# psoc4hvpaspm10 register map
Vendor: Infineon Technologies; Series: PSOC4HVPASPM10; File version: 1.0
CPU: CM0PLUS r0p1, little endian, MPU, no FPU, VTOR, 2 interrupt priority bits, 32 interrupts
Registers are 32-bit, read-write, reset 0x0 unless marked. A register's access mark holds for its fields unless they carry their own. Offsets are from the block's base; [hi:lo] are bit positions; lines under a group give offsets from that group.

## CANFD0 (part 2 of 3) — CAN Controller
Base 0x40220000
0x00 CH group — FIFO wrapper around M_TTCAN 3PIP, to enable DMA
  0x00 M_TTCAN group — TTCAN 3PIP, includes FD
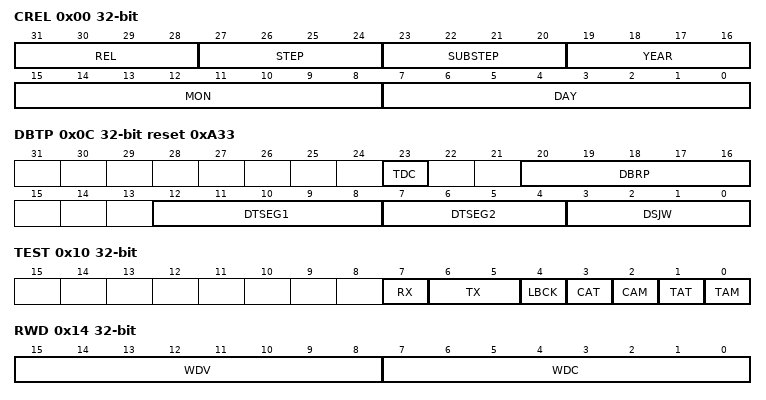
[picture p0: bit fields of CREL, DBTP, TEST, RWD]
    0x00 CREL ro — Core Release Register
      [31:28] REL — Core Release One digit, BCD-coded.
      [27:24] STEP — Step of Core Release One digit, BCD-coded.
      [23:20] SUBSTEP — Sub-step of Core Release One digit, BCD-coded.
      [19:16] YEAR — Time Stamp Year One digit, BCD-coded. This field is set by generic parameter on M_TTCAN synthesis.
      [15:8] MON — Time Stamp Month Two digits, BCD-coded. This field is set by generic parameter on M_TTCAN synthesis.
      [7:0] DAY — Time Stamp Day Two digits, BCD-coded. This field is set by generic parameter on M_TTCAN synthesis.
    0x04 ENDN ro reset 0x87654321 — Endian Register
      [31:0] ETV — Endianness Test Value The endianness test value is 0x87654321.
    0x0C DBTP reset 0xA33 — Data Bit Timing & Prescaler Register
      [23] TDC — Transmitter Delay Compensation 0= Transmitter Delay Compensation disabled 1= Transmitter Delay Compensation enabled
      [20:16] DBRP — Data Bit Rate Prescaler 0x00-0x1F The value by which the oscillator frequency is divided for generating the bit time quanta. The bit time is built up from a multiple of this quanta. Valid values for the Bit Rate Prescaler are 0 to 31. The actual interpretation by the hardware of this value is such that one more than the value programmed here is used.
      [12:8] DTSEG1 — Data time segment before sample point 0x00-0x1F Valid values are 0 to 31. The actual interpretation by the hardware of this value is such that one more than the programmed value is used.
      [7:4] DTSEG2 — Data time segment after sample point 0x0-0xF Valid values are 0 to 15. The actual interpretation by the hardware of this value is such that one more than the programmed value is used.
      [3:0] DSJW — Data (Re)Synchronization Jump Width 0x0-0xF Valid values are 0 to 15. The actual interpretation by the hardware of this value is such that one more than the value programmed here is used.
    0x10 TEST (reset mask 0x7F)
      [7] RX ro — Receive Pin Monitors the actual value of pin m_ttcan_rx 0= The CAN bus is dominant (m_ttcan_rx = '0') 1= The CAN bus is recessive (m_ttcan_rx = '1')
      [6:5] TX — Control of Transmit Pin 00 Reset value, m_ttcan_tx controlled by the CAN Core, updated at the end of the CAN bit time 01 Sample Point can be monitored at pin m_ttcan_tx 10 Dominant ('0') level at pin m_ttcan_tx 11 Recessive ('1') at pin m_ttcan_tx
      [4] LBCK — Loop Back Mode 0= Reset value, Loop Back Mode is disabled 1= Loop Back Mode is enabled (see Section 3.1.9, Test Modes)
      [3] CAT — ASC is not supported by M_TTCAN Check ASC Transmit Control Monitors level at output pin m_ttcan_asct. 0= Output pin m_ttcan_asct = '0'
      [2] CAM — ASC is not supported by M_TTCAN Check ASC Multiplexer Control Monitors level at output pin m_ttcan_ascm. 0= Output pin m_ttcan_ascm = '0' 1= Output pin m_ttcan_ascm = '1'
      [1] TAT — ASC is not supported by M_TTCAN Test ASC Transmit Control Controls output pin m_ttcan_asct in test mode, ORed with the signal from the FSE 0= Level at pin m_ttcan_asct controlled by FSE 1= Level at pin m_ttcan_asct = '1'
      [0] TAM — ASC is not supported by M_TTCAN Test ASC Multiplexer Control Controls output pin m_ttcan_ascm in test mode, ORed with the signal from the FSE 0= Level at pin m_ttcan_ascm controlled by FSE 1= Level at pin m_ttcan_ascm = '1'
    0x14 RWD — RAM Watchdog
      [15:8] WDV ro — Watchdog Value Actual Message RAM Watchdog Counter Value.
      [7:0] WDC — Watchdog Configuration Start value of the Message RAM Watchdog Counter. With the reset value of '00' the counter is disabled.
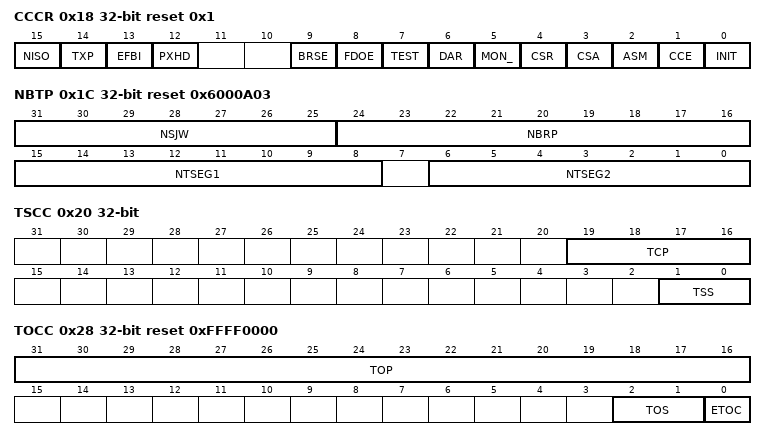
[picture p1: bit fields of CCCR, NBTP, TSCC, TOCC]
    0x18 CCCR reset 0x1 — CC Control Register
      [15] NISO — Non ISO Operation If this bit is set, the M_TTCAN uses the CAN FD frame format as specified by the Bosch CAN FD Specification V1.0. 0= CAN FD frame format according to ISO 11898-1:2015 1= CAN FD frame format according to Bosch CAN FD Specification V1.0 addressing the non-ISO CAN FD
      [14] TXP — Transmit Pause If this bit is set, the M_TTCAN pauses for two CAN bit times before starting the next transmission after itself has successfully transmitted a frame (see Section 3.5). 0= Transmit pause disabled 1= Transmit pause enabled
      [13] EFBI — Edge Filtering during Bus Integration 0= Edge filtering disabled 1= Two consecutive dominant tq required to detect an edge for hard synchronization
      [12] PXHD — Protocol Exception Handling Disable 0= Protocol exception handling enabled 1= Protocol exception handling disabled
      [9] BRSE — Bit Rate Switch Enable 0= Bit rate switching for transmissions disabled 1= Bit rate switching for transmissions enabled
      [8] FDOE — FD Operation Enable 0= FD operation disabled 1= FD operation enabled
      [7] TEST — Test Mode Enable 0= Normal operation, register TEST holds reset values 1= Test Mode, write access to register TEST enabled
      [6] DAR — Disable Automatic Retransmission 0= Automatic retransmission of messages not transmitted successfully enabled 1= Automatic retransmission disabled
      [5] MON_ — Bus Monitoring Mode Bit MON can only be set by the Host when both CCE and INIT are set to '1'. The bit can be reset by the Host at any time. 0= Bus Monitoring Mode is disabled 1= Bus Monitoring Mode is enabled
      [4] CSR — Clock Stop Request, not supported by M_TTCAN use CTL.STOP_REQ at the group level instead. 0= No clock stop is requested 1= Clock stop requested. When clock stop is requested, first INIT and then CSA will be set after all pending transfer requests have been completed and the CAN bus reached idle.
      [3] CSA — Clock Stop Acknowledge 0= No clock stop acknowledged 1= M_TTCAN may be set in power down by stopping m_ttcan_hclk and m_ttcan_cclk
      [2] ASM — Restricted Operation Mode Bit ASM can only be set by the Host when both CCE and INIT are set to '1'. The bit can be reset by the Host at any time. For a description of the Restricted Operation Mode see Section 3.1.5. 0= Normal CAN operation 1= Restricted Operation Mode active
      [1] CCE — Configuration Change Enable 0= The CPU has no write access to the protected configuration registers 1= The CPU has write access to the protected configuration registers (while CCCR.INIT = '1')
      [0] INIT — Initialization 0= Normal Operation 1= Initialization is started
    0x1C NBTP reset 0x6000A03 — Nominal Bit Timing & Prescaler Register
      [31:25] NSJW — Nominal (Re)Synchronization Jump Width 0x00-0x7F Valid values are 0 to 127. The actual interpretation by the hardware of this value is such that one more than the value programmed here is used.
      [24:16] NBRP — Nominal Bit Rate Prescaler 0x000-0x1FFThe value by which the oscillator frequency is divided for generating the bit time quanta. The bit time is built up from a multiple of this quanta. Valid values for the Bit Rate Prescaler are 0 to 511. The actual interpretation by the hardware of this value is such that one more than the value programmed here is used.
      [15:8] NTSEG1 — Nominal Time segment before sample point 0x01-0xFF Valid values are 1 to 255. The actual interpretation by the hardware of this value is such that one more than the programmed value is used.
      [6:0] NTSEG2 — Nominal Time segment after sample point 0x01-0x7F Valid values are 1 to 127. The actual interpretation by the hardware of this value is such that one more than the programmed value is used.
    0x20 TSCC — Timestamp Counter Configuration
      [19:16] TCP — Timestamp Counter Prescaler (still used for TOCC) 0x0-0xF Configures the timestamp and timeout counters time unit in multiples of CAN bit times [1...16]. The actual interpretation by the hardware of this value is such that one more than the value programmed here is used.
      [1:0] TSS — Timestamp Select, should always be set to external timestamp counter 00= Timestamp counter value always 0x0000 01= Timestamp counter value incremented according to TCP 10= External timestamp counter value used 11= Same as '00'
    0x24 TSCV — Timestamp Counter Value
      [15:0] TSC — Timestamp Counter, not used for M_TTCAN The internal/external Timestamp Counter value is captured on start of frame (both Rx and Tx). When TSCC.TSS = '01', the Timestamp Counter is incremented in multiples of CAN bit times [1...16] depending on the configuration of TSCC.TCP. A wrap around sets interrupt flag IR.TSW. Write access resets the counter to zero. When TSCC.TSS = '10', TSC reflects the external Timestamp Counter value. A write access has no impact.
    0x28 TOCC reset 0xFFFF0000 — Timeout Counter Configuration
      [31:16] TOP — Timeout Period Start value of the Timeout Counter (down-counter). Configures the Timeout Period.
      [2:1] TOS — Timeout Select When operating in Continuous mode, a write to TOCV presets the counter to the value configured by TOCC.TOP and continues down-counting. When the Timeout Counter is controlled by one of the FIFOs, an empty FIFO presets the counter to the value configured by TOCC.TOP. Down-counting is started when the first FIFO element is stored. 00= Continuous operation 01= Timeout controlled by Tx Event FIFO 10= Timeout controlled by Rx FIFO 0 11= Timeout controlled by Rx FIFO 1
      [0] ETOC — Enable Timeout Counter 0= Timeout Counter disabled 1= Timeout Counter enabled
    0x2C TOCV reset 0xFFFF — Timeout Counter Value
      [15:0] TOC — Timeout Counter The Timeout Counter is decremented in multiples of CAN bit times [1...16] depending on the configuration of TSCC.TCP. When decremented to zero, interrupt flag IR.TOO is set and the Timeout Counter is stopped. Start and reset/restart conditions are configured via TOCC.TOS.
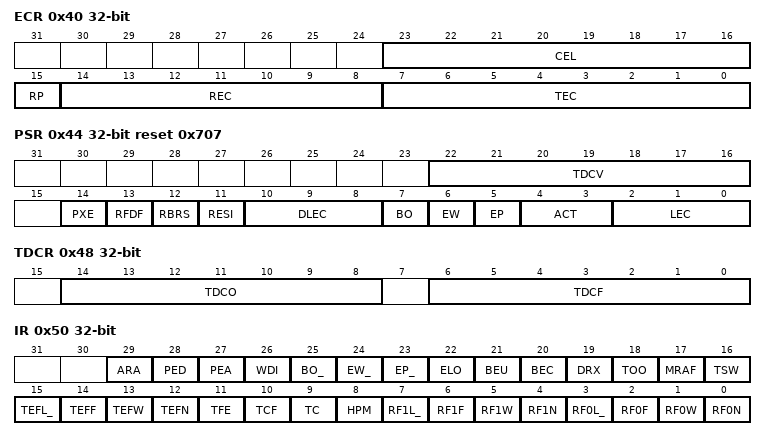
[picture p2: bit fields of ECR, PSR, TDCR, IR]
    0x40 ECR ro — Error Counter Register
      [23:16] CEL — CAN Error Logging The counter is incremented each time when a CAN protocol error causes the Transmit Error Counter or the Receive Error Counter to be incremented. It is reset by read access to CEL. The counter stops at 0xFF; the next increment of TEC or REC sets interrupt flag IR.ELO.
      [15] RP — Receive Error Passive 0= The Receive Error Counter is below the error passive level of 128 1= The Receive Error Counter has reached the error passive level of 128
      [14:8] REC — Receive Error Counter Actual state of the Receive Error Counter, values between 0 and 127
      [7:0] TEC — Transmit Error Counter Actual state of the Transmit Error Counter, values between 0 and 255
    0x44 PSR ro reset 0x707 — Protocol Status Register
      [22:16] TDCV — Transmitter Delay Compensation Value 0x00-0x7F Position of the secondary sample point, defined by the sum of the measured delay from m_can_tx to m_can_rx and TDCR.TDCO. The SSP position is, in the data phase, the number of mtq between the start of the transmitted bit and the secondary sample point. Valid values are 0 to 127 mtq.
      [14] PXE — Protocol Exception Event , Reset on Read 0= No protocol exception event occurred since last read access 1= Protocol exception event occurred
      [13] RFDF — Received a CAN FD Message , Reset on Read This bit is set independent of acceptance filtering. 0= Since this bit was reset by the CPU, no CAN FD message has been received 1= Message in CAN FD format with FDF flag set has been received
      [12] RBRS — BRS flag of last received CAN FD Message , Reset on Read This bit is set together with RFDF, independent of acceptance filtering. 0= Last received CAN FD message did not have its BRS flag set 1= Last received CAN FD message had its BRS flag set
      [11] RESI — ESI flag of last received CAN FD Message , Reset on Read This bit is set together with RFDF, independent of acceptance filtering. 0= Last received CAN FD message did not have its ESI flag set 1= Last received CAN FD message had its ESI flag set
      [10:8] DLEC — Data Phase Last Error Code , Set on Read Type of last error that occurred in the data phase of a CAN FD format frame with its BRS flag set. Coding is the same as for LEC. This field will be cleared to zero when a CAN FD format frame with its BRS flag set has been transferred (reception or transmission) without error.
      [7] BO — Bus_Off Status 0= The M_CAN is not Bus_Off 1= The M_CAN is in Bus_Off state
      [6] EW — Warning Status 0= Both error counters are below the Error_Warning limit of 96 1= At least one of error counter has reached the Error_Warning limit of 96
      [5] EP — Error Passive 0= The M_CAN is in the Error_Active state. It normally takes part in bus communication and sends an active error flag when an error has been detected 1= The M_CAN is in the Error_Passive state
      [4:3] ACT — Activity Monitors the module's CAN communication state. 00= Synchronizing - node is synchronizing on CAN communication 01= Idle - node is neither receiver nor transmitter 10= Receiver - node is operating as receiver 11= Transmitter - node is operating as transmitter
      [2:0] LEC — Last Error Code, Set on Read0 The LEC indicates the type of the last error to occur on the CAN bus. This field will be cleared to '0' when a message has been transferred (reception or transmission) without error. 0= No Error: No error occurred since LEC has been reset by successful reception or transmission. 1= Stuff Error: More than 5 equal bits in a sequence have occurred in a part of a received message where this is not allowed. 2= Form Error: A fixed format part of a received frame has the wrong format. 3= AckError: The message transmitted by the M_TTCAN was not acknowledged by another node. 4= Bit1Error: During the transmission of a message (with the exception of the arbitration field), the device wanted to send a recessive level (bit of logical value '1'), but the monitored bus value was dominant. 5= Bit0Error: During the transmission of a message (or acknowledge bit, or active error flag, or overload flag), the device wanted to send a dominant level (data or identifier bit logical value 0'), but the monitored bus value was recessive. During Bus_Off recovery this status is set each time a sequence of 11 recessive bits has been monitored. This enables the CPU to monitor the proceeding of the Bus_Off recovery sequence (indicating the bus is not stuck at dominant or continuously disturbed). 6= CRCError: The CRC check sum of a received message was incorrect. The CRC of an incoming message does not match with the CRC calculated from the received data. 7= NoChange: Any read access to the Protocol Status Register re-initializes the LEC to '7'. When the LEC shows the value '7', no CAN bus event was detected since the last CPU read access to the Protocol Status Register.
    0x48 TDCR — Transmitter Delay Compensation Register
      [14:8] TDCO — Transmitter Delay Compensation Offset 0x00-0x7F Offset value defining the distance between the measured delay from m_ttcan_tx to m_ttcan_rx and the secondary sample point. Valid values are 0 to 127 mtq.
      [6:0] TDCF — Transmitter Delay Compensation Filter Window Length 0x00-0x7F Defines the minimum value for the SSP position, dominant edges on m_ttcan_rx that would result in an earlier SSP position are ignored for transmitter delay measurement. The feature is enabled when TDCF is configured to a value greater than TDCO. Valid values are 0 to 127 mtq
    0x50 IR — Interrupt Register
      [29] ARA write-1-clears
      [28] PED write-1-clears — Protocol Error in Data Phase (Data Bit Time is used) 0= No protocol error in data phase 1= Protocol error in data phase detected (PSR.DLEC != 0,7)
      [27] PEA write-1-clears — Protocol Error in Arbitration Phase (Nominal Bit Time is used) 0= No protocol error in arbitration phase 1= Protocol error in arbitration phase detected (PSR.LEC != 0,7)
      [26] WDI write-1-clears — Watchdog Interrupt 0= No Message RAM Watchdog event occurred 1= Message RAM Watchdog event due to missing READY
      [25] BO_ write-1-clears — Bus_Off Status 0= Bus_Off status unchanged 1= Bus_Off status changed
      [24] EW_ write-1-clears — Warning Status 0= Error_Warning status unchanged 1= Error_Warning status changed
      [23] EP_ write-1-clears — Error Passive 0= Error_Passive status unchanged 1= Error_Passive status changed
      [22] ELO write-1-clears — Error Logging Overflow 0= CAN Error Logging Counter did not overflow 1= Overflow of CAN Error Logging Counter occurred
      [21] BEU write-1-clears — Bit Error Uncorrected Message RAM bit error detected, uncorrected. Controlled by input signal m_ttcan_aeim_berr[1] generated by an optional external parity / ECC logic attached to the Message RAM. An uncorrected Message RAM bit error sets CCCR.INIT to '1'. This is done to avoid transmission of corrupted data. 0= No bit error detected when reading from Message RAM 1= Bit error detected, uncorrected (e.g. parity logic)
      [20] BEC write-1-clears — M_TTCAN reports correctable ECC fault to the generic fault structure, this bit always reads as 0. Bit Error Corrected Message RAM bit error detected and corrected. Controlled by input signal m_ttcan_aeim_berr[0] generated by an optional external parity / ECC logic attached to the Message RAM. 0= No bit error detected when reading from Message RAM 1= Bit error detected and corrected (e.g. ECC)
      [19] DRX write-1-clears — Message stored to Dedicated Rx Buffer The flag is set whenever a received message has been stored into a dedicated Rx Buffer. 0= No Rx Buffer updated 1= At least one received message stored into a Rx Buffer
      [18] TOO write-1-clears — Timeout Occurred 0= No timeout 1= Timeout reached
      [17] MRAF write-1-clears — Message RAM Access Failure The flag is set, when the Rx Handler - has not completed acceptance filtering or storage of an accepted message until the arbitration field of the following message has been received. In this case acceptance filtering or message storage is aborted and the Rx Handler starts processing of the following message. - was not able to write a message to the Message RAM. In this case message storage is aborted. In both cases the FIFO put index is not updated resp. the New Data flag for a dedicated Rx Buffer is not set, a partly stored message is overwritten when the next message is stored to this location. The flag is also set when the Tx Handler was not able to read a message from the Message RAM in time. In this case message transmission is aborted. In case of a Tx Handler access failure the M_TTCAN is switched into Restricted Operation Mode (see Section 3.1.5). To leave Restricted Operation Mode, the Host CPU has to reset CCCR.ASM. 0= No Message RAM access failure occurred 1= Message RAM access failure occurred
      [16] TSW write-1-clears — Timestamp Wraparound 0= No timestamp counter wrap-around 1= Timestamp counter wrapped around
      [15] TEFL_ write-1-clears — Tx Event FIFO Element Lost 0= No Tx Event FIFO element lost 1= Tx Event FIFO element lost, also set after write attempt to Tx Event FIFO of size zero
      [14] TEFF write-1-clears — Tx Event FIFO Full 0= Tx Event FIFO not full 1= Tx Event FIFO full
      [13] TEFW write-1-clears — Tx Event FIFO Watermark Reached 0= Tx Event FIFO fill level below watermark 1= Tx Event FIFO fill level reached watermark
      [12] TEFN write-1-clears — Tx Event FIFO New Entry 0= Tx Event FIFO unchanged 1= Tx Handler wrote Tx Event FIFO element
      [11] TFE write-1-clears — Tx FIFO Empty 0= Tx FIFO non-empty 1= Tx FIFO empty
      [10] TCF write-1-clears — Transmission Cancellation Finished 0= No transmission cancellation finished 1= Transmission cancellation finished
      [9] TC write-1-clears — Transmission Completed 0= No transmission completed 1= Transmission completed
      [8] HPM write-1-clears — High Priority Message 0= No high priority message received 1= High priority message received
      [7] RF1L_ write-1-clears — Rx FIFO 1 Message Lost 0= No Rx FIFO 1 message lost 1= Rx FIFO 1 message lost, also set after write attempt to Rx FIFO 1 of size zero
      [6] RF1F write-1-clears — Rx FIFO 1 Full 0= Rx FIFO 1 not full 1= Rx FIFO 1 full
      [5] RF1W write-1-clears — Rx FIFO 1 Watermark Reached 0= Rx FIFO 1 fill level below watermark 1= Rx FIFO 1 fill level reached watermark
      [4] RF1N write-1-clears — Rx FIFO 1 New Message 0= No new message written to Rx FIFO 1 1= New message written to Rx FIFO 1
      [3] RF0L_ write-1-clears — Rx FIFO 0 Message Lost 0= No Rx FIFO 0 message lost 1= Rx FIFO 0 message lost, also set after write attempt to Rx FIFO 0 of size zero
      [2] RF0F write-1-clears — Rx FIFO 0 Full 0= Rx FIFO 0 not full 1= Rx FIFO 0 full
      [1] RF0W write-1-clears — Rx FIFO 0 Watermark Reached 0= Rx FIFO 0 fill level below watermark 1= Rx FIFO 0 fill level reached watermark
      [0] RF0N write-1-clears — Rx FIFO 0 New Message 0= No new message written to Rx FIFO 0 1= New message written to Rx FIFO 0
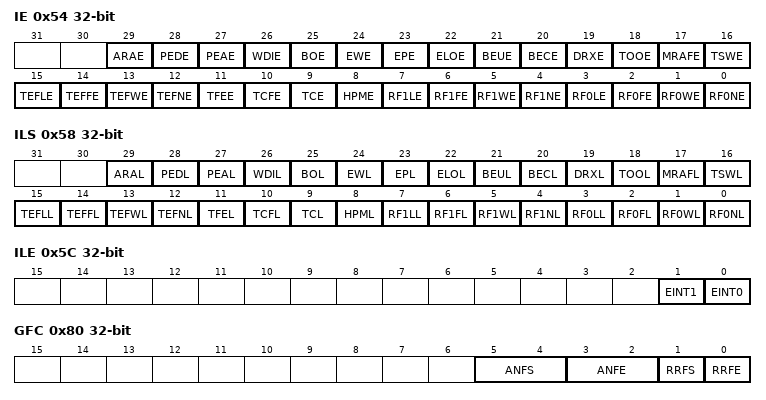
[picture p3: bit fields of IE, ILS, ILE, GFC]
    0x54 IE — Interrupt Enable
      [29] ARAE
      [28] PEDE — Protocol Error in Data Phase Enable 0= Interrupt Disabled 1= Interrupt Enabled
      [27] PEAE — Protocol Error in Arbitration Phase Enable 0= Interrupt Disabled 1= Interrupt Enabled
      [26] WDIE — Watchdog Interrupt Enable 0= Interrupt Disabled 1= Interrupt Enabled
      [25] BOE — Bus_Off Status Interrupt Enable 0= Interrupt Disabled 1= Interrupt Enabled
      [24] EWE — Warning Status Interrupt Enable 0= Interrupt Disabled 1= Interrupt Enabled
      [23] EPE — Error Passive Interrupt Enable 0= Interrupt Disabled 1= Interrupt Enabled
      [22] ELOE — Error Logging Overflow Interrupt Enable 0= Interrupt Disabled 1= Interrupt Enabled
      [21] BEUE — Bit Error Uncorrected Interrupt Enable 0= Interrupt Disabled 1= Interrupt Enabled
      [20] BECE — Bit Error Corrected Interrupt Enable (not used in M_TTCAN) 0= Interrupt Disabled 1= Interrupt Enabled
      [19] DRXE — Message stored to Dedicated Rx Buffer Interrupt Enable 0= Interrupt Disabled 1= Interrupt Enabled
      [18] TOOE — Timeout Occurred Interrupt Enable 0= Interrupt Disabled 1= Interrupt Enabled
      [17] MRAFE — Message RAM Access Failure Interrupt Enable 0= Interrupt Disabled 1= Interrupt Enabled
      [16] TSWE — Timestamp Wraparound Interrupt Enable 0= Interrupt Disabled 1= Interrupt Enabled
      [15] TEFLE — Tx Event FIFO Event Lost Interrupt Enable 0= Interrupt Disabled 1= Interrupt Enabled
      [14] TEFFE — Tx Event FIFO Full Interrupt Enable 0= Interrupt Disabled 1= Interrupt Enabled
      [13] TEFWE — Tx Event FIFO Watermark Reached Interrupt Enable 0= Interrupt Disabled 1= Interrupt Enabled
      [12] TEFNE — Tx Event FIDO New Entry Interrupt Enable 0= Interrupt Disabled 1= Interrupt Enabled
      [11] TFEE — Tx FIFO Empty Interrupt Enable 0= Interrupt Disabled 1= Interrupt EnabledTx FIFO Empty Interrupt Enable
      [10] TCFE — Transmission Cancellation Finished Interrupt Enable 0= Interrupt Disabled 1= Interrupt Enabled
      [9] TCE — Transmission Completed Interrupt Enable 0= Interrupt Disabled 1= Interrupt Enabled
      [8] HPME — High Priority Message Interrupt Enable 0= Interrupt Disabled 1= Interrupt Enabled
      [7] RF1LE — Rx FIFO 1 Message Lost Interrupt Enable 0= Interrupt Disabled 1= Interrupt Enabled
      [6] RF1FE — Rx FIFO 1 Full Interrupt Enable 0= Interrupt Disabled 1= Interrupt Enabled
      [5] RF1WE — Rx FIFO 1 Watermark Reached Interrupt Enable 0= Interrupt Disabled 1= Interrupt Enabled
      [4] RF1NE — Rx FIFO 1 New Message Interrupt Enable 0= Interrupt Disabled 1= Interrupt Enabled
      [3] RF0LE — Rx FIFO 0 Message Lost Interrupt Enable 0= Interrupt Disabled 1= Interrupt Enabled
      [2] RF0FE — Rx FIFO 0 Full Interrupt Enable 0= Interrupt Disabled 1= Interrupt Enabled
      [1] RF0WE — Rx FIFO 0 Watermark Reached Interrupt Enable 0= Interrupt Disabled 1= Interrupt Enabled
      [0] RF0NE — Rx FIFO 0 New Message Interrupt Enable 0= Interrupt Disabled 1= Interrupt Enabled
    0x58 ILS — Interrupt Line Select
      [29] ARAL
      [28] PEDL — Protocol Error in Data Phase Select 0= Assign to interrupt enabled by ILE.EINT0 1= Assign to interrupt enabled by ILE.EINT1
      [27] PEAL — Protocol Error in Arbitration Phase Select 0= Assign to interrupt enabled by ILE.EINT0 1= Assign to interrupt enabled by ILE.EINT1
      [26] WDIL — Watchdog Interrupt Select 0= Assign to interrupt enabled by ILE.EINT0 1= Assign to interrupt enabled by ILE.EINT1
      [25] BOL — Bus_Off Status Interrupt Select 0= Assign to interrupt enabled by ILE.EINT0 1= Assign to interrupt enabled by ILE.EINT1
      [24] EWL — Warning Status Interrupt Select 0= Assign to interrupt enabled by ILE.EINT0 1= Assign to interrupt enabled by ILE.EINT1
      [23] EPL — Error Passive Interrupt Select 0= Assign to interrupt enabled by ILE.EINT0 1= Assign to interrupt enabled by ILE.EINT1
      [22] ELOL — Error Logging Overflow Interrupt Select 0= Assign to interrupt enabled by ILE.EINT0 1= Assign to interrupt enabled by ILE.EINT1
      [21] BEUL — Bit Error Uncorrected Interrupt Select 0= Assign to interrupt enabled by ILE.EINT0 1= Assign to interrupt enabled by ILE.EINT1
      [20] BECL — Bit Error Corrected Interrupt Select (not used in M_TTCAN) 0= Assign to interrupt enabled by ILE.EINT0 1= Assign to interrupt enabled by ILE.EINT1
      [19] DRXL — Message stored to Dedicated Rx Buffer Interrupt Select 0= Assign to interrupt enabled by ILE.EINT0 1= Assign to interrupt enabled by ILE.EINT1
      [18] TOOL — Timeout Occurred Interrupt Select 0= Assign to interrupt enabled by ILE.EINT0 1= Assign to interrupt enabled by ILE.EINT1
      [17] MRAFL — Message RAM Access Failure Interrupt Select 0= Assign to interrupt enabled by ILE.EINT0 1= Assign to interrupt enabled by ILE.EINT1
      [16] TSWL — Timestamp Wraparound Interrupt Select 0= Assign to interrupt enabled by ILE.EINT0 1= Assign to interrupt enabled by ILE.EINT1
      [15] TEFLL — Tx Event FIFO Event Lost Interrupt Select 0= Assign to interrupt enabled by ILE.EINT0 1= Assign to interrupt enabled by ILE.EINT1
      [14] TEFFL — Tx Event FIFO Full Interrupt Select 0= Assign to interrupt enabled by ILE.EINT0 1= Assign to interrupt enabled by ILE.EINT1
      [13] TEFWL — Tx Event FIFO Watermark Reached Interrupt Select 0= Assign to interrupt enabled by ILE.EINT0 1= Assign to interrupt enabled by ILE.EINT1
      [12] TEFNL — Tx Event FIFO New Entry Interrupt Select 0= Assign to interrupt enabled by ILE.EINT0 1= Assign to interrupt enabled by ILE.EINT1
      [11] TFEL — Tx FIFO Empty Interrupt Select 0= Assign to interrupt enabled by ILE.EINT0 1= Assign to interrupt enabled by ILE.EINT1
      [10] TCFL — Transmission Cancellation Finished Interrupt Select 0= Assign to interrupt enabled by ILE.EINT0 1= Assign to interrupt enabled by ILE.EINT1
      [9] TCL — Transmission Completed Interrupt Select 0= Assign to interrupt enabled by ILE.EINT0 1= Assign to interrupt enabled by ILE.EINT1
      [8] HPML — High Priority Message Interrupt Select 0= Assign to interrupt enabled by ILE.EINT0 1= Assign to interrupt enabled by ILE.EINT1
      [7] RF1LL — Rx FIFO 1 Message Lost Interrupt Select 0= Assign to interrupt enabled by ILE.EINT0 1= Assign to interrupt enabled by ILE.EINT1
      [6] RF1FL — Rx FIFO 1 Full Interrupt Select 0= Assign to interrupt enabled by ILE.EINT0 1= Assign to interrupt enabled by ILE.EINT1
      [5] RF1WL — Rx FIFO 1 Watermark Reached Interrupt Select 0= Assign to interrupt enabled by ILE.EINT0 1= Assign to interrupt enabled by ILE.EINT1
      [4] RF1NL — Rx FIFO 1 New Message Interrupt Select 0= Assign to interrupt enabled by ILE.EINT0 1= Assign to interrupt enabled by ILE.EINT1
      [3] RF0LL — Rx FIFO 0 Message Lost Interrupt Select 0= Assign to interrupt enabled by ILE.EINT0 1= Assign to interrupt enabled by ILE.EINT1
      [2] RF0FL — Rx FIFO 0 Full Interrupt Select 0= Assign to interrupt enabled by ILE.EINT0 1= Assign to interrupt enabled by ILE.EINT1
      [1] RF0WL — Rx FIFO 0 Watermark Reached Interrupt Select 0= Assign to interrupt enabled by ILE.EINT0 1= Assign to interrupt enabled by ILE.EINT1
      [0] RF0NL — Rx FIFO 0 New Message Interrupt Select 0= Assign to interrupt enabled by ILE.EINT0 1= Assign to interrupt enabled by ILE.EINT1
    0x5C ILE — Interrupt Line Enable
      [1] EINT1 — Enable Interrupt Line 1 0= Interrupt line m_ttcan_int1 disabled 1= Interrupt line m_ttcan_int1 enabled
      [0] EINT0 — Enable Interrupt Line 0 0= Interrupt line m_ttcan_int0 disabled 1= Interrupt line m_ttcan_int0 enabled
    0x80 GFC — Global Filter Configuration
      [5:4] ANFS — Accept Non-matching Frames Standard Defines how received messages with 11-bit IDs that do not match any element of the filter list are treated. 00= Accept in Rx FIFO 0 01= Accept in Rx FIFO 1 10= Reject 11= Reject
      [3:2] ANFE — Accept Non-matching Frames Extended Defines how received messages with 29-bit IDs that do not match any element of the filter list are treated. 00= Accept in Rx FIFO 0 01= Accept in Rx FIFO 1 10= Reject 11= Reject
      [1] RRFS — Reject Remote Frames Standard 0= Filter remote frames with 11-bit standard IDs 1= Reject all remote frames with 11-bit standard IDs
      [0] RRFE — Reject Remote Frames Extended 0= Filter remote frames with 29-bit extended IDs 1= Reject all remote frames with 29-bit extended IDs
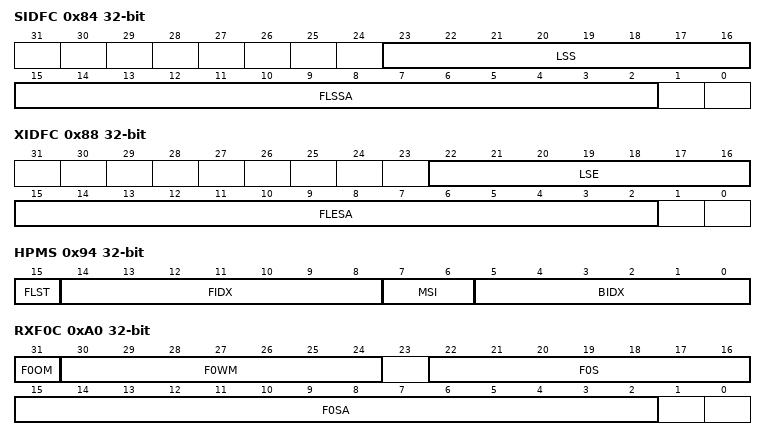
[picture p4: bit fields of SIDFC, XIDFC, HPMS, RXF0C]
    0x84 SIDFC — Standard ID Filter Configuration
      [23:16] LSS — List Size Standard 0= No standard Message ID filter 1-128= Number of standard Message ID filter elements 128= Values greater than 128 are interpreted as 128
      [15:2] FLSSA — Filter List Standard Start Address Start address of standard Message ID filter list (32-bit word address, see Figure 2).
    0x88 XIDFC — Extended ID Filter Configuration
      [22:16] LSE — List Size Extended 0= No extended Message ID filter 1-64= Number of extended Message ID filter elements 64= Values greater than 64 are interpreted as 64
      [15:2] FLESA — Filter List Extended Start Address Start address of extended Message ID filter list (32-bit word address, see Figure 2).
    0x90 XIDAM — Extended ID AND Mask
      [28:0] EIDM — Extended ID Mask For acceptance filtering of extended frames the Extended ID AND Mask is ANDed with the Message ID of a received frame. Intended for masking of 29-bit IDs in SAE J1939. With the reset value of all bits set to one the mask is not active.
    0x94 HPMS ro — High Priority Message Status
      [15] FLST — Filter List Indicates the filter list of the matching filter element. 0= Standard Filter List 1= Extended Filter List
      [14:8] FIDX — Filter Index Index of matching filter element. Range is 0 to SIDFC.LSS - 1 resp. XIDFC.LSE - 1.
      [7:6] MSI — Message Storage Indicator 00= No FIFO selected 01= FIFO message lost 10= Message stored in FIFO 0 11= Message stored in FIFO 1
      [5:0] BIDX — Buffer Index Index of Rx FIFO element to which the message was stored. Only valid when MSI[1] = '1'.
    0x98 NDAT1 — New Data 1
      [31:0] ND write-1-clears — New Data The register holds the New Data flags of Rx Buffers 0 to 31. The flags are set when the respective Rx Buffer has been updated from a received frame. The flags remain set until the Host clears them. A flag is cleared by writing a '1' to the corresponding bit position. Writing a '0' has no effect. A hard reset will clear the register. 0= Rx Buffer not updated 1= Rx Buffer updated from new message
    0x9C NDAT2 — New Data 2
      [31:0] ND write-1-clears — New Data The register holds the New Data flags of Rx Buffers 32 to 63. The flags are set when the respective Rx Buffer has been updated from a received frame. The flags remain set until the Host clears them. A flag is cleared by writing a '1' to the corresponding bit position. Writing a '0' has no effect. A hard reset will clear the register. 0= Rx Buffer not updated 1= Rx Buffer updated from new message
    0xA0 RXF0C — Rx FIFO 0 Configuration
      [31] F0OM — FIFO 0 Operation Mode FIFO 0 can be operated in blocking or in overwrite mode (see Section 3.4.2). 0= FIFO 0 blocking mode 1= FIFO 0 overwrite mode
      [30:24] F0WM — Rx FIFO 0 Watermark 0= Watermark interrupt disabled 1-64= Level for Rx FIFO 0 watermark interrupt (IR.RF0W) 64= Watermark interrupt disabled
      [22:16] F0S — Rx FIFO 0 Size 0= No Rx FIFO 0 1-64= Number of Rx FIFO 0 elements 64= Values greater than 64 are interpreted as 64 The Rx FIFO 0 elements are indexed from 0 to F0S-1
      [15:2] F0SA — Rx FIFO 0 Start Address Start address of Rx FIFO 0 in Message RAM (32-bit word address, see Figure 2).
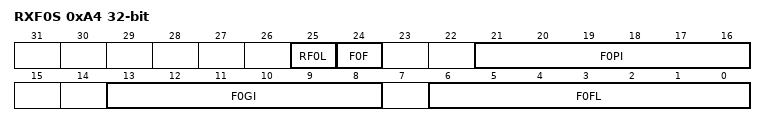
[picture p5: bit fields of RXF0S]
    0xA4 RXF0S ro — Rx FIFO 0 Status
      [25] RF0L — Rx FIFO 0 Message Lost This bit is a copy of interrupt flag IR.RF0L. When IR.RF0L is reset, this bit is also reset. 0= No Rx FIFO 0 message lost 1= Rx FIFO 0 message lost, also set after write attempt to Rx FIFO 0 of size zero
      [24] F0F — Rx FIFO 0 Full 0= Rx FIFO 0 not full 1= Rx FIFO 0 full
      [21:16] F0PI — Rx FIFO 0 Put Index Rx FIFO 0 write index pointer, range 0 to 63.
      [13:8] F0GI — Rx FIFO 0 Get Index Rx FIFO 0 read index pointer, range 0 to 63. This field is updated by the software writing to RxF0A.F0AI
      [6:0] F0FL — Rx FIFO 0 Fill Level Number of elements stored in Rx FIFO 0, range 0 to 64.
